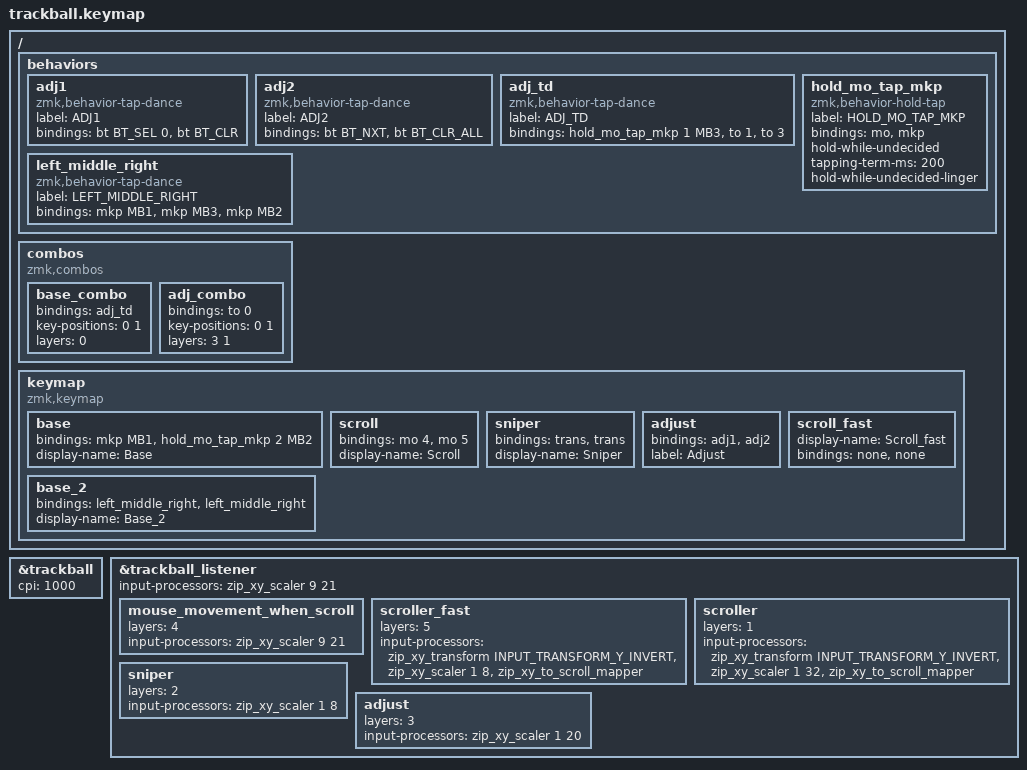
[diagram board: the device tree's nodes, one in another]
#include "keys_ru.h"
#include <dt-bindings/zmk/input_transform.h>
#include <input/processors.dtsi>
#include <zephyr/dt-bindings/input/input-event-codes.h>
#include <behaviors.dtsi>
#include <dt-bindings/zmk/bt.h>
#include <dt-bindings/zmk/pointing.h>

/ {
    behaviors {
        adj1: adj1 {
            compatible = "zmk,behavior-tap-dance";
            label = "ADJ1";
            #binding-cells = <0>;
            bindings = <&bt BT_SEL 0>, <&bt BT_CLR>;
        };

        adj2: adj2 {
            compatible = "zmk,behavior-tap-dance";
            label = "ADJ2";
            #binding-cells = <0>;
            bindings = <&bt BT_NXT>, <&bt BT_CLR_ALL>;
        };

        adj_td: adj_td {
            compatible = "zmk,behavior-tap-dance";
            label = "ADJ_TD";
            #binding-cells = <0>;
            bindings = <&hold_mo_tap_mkp 1 MB3>, <&to 1>, <&to 3>;
        };

        hold_mo_tap_mkp: hold_mo_tap_mkp {
            compatible = "zmk,behavior-hold-tap";
            label = "HOLD_MO_TAP_MKP";
            bindings = <&mo>, <&mkp>;

            #binding-cells = <2>;
            hold-while-undecided;
            tapping-term-ms = <200>;
            hold-while-undecided-linger;
        };

        left_middle_right: left_middle_right {
            compatible = "zmk,behavior-tap-dance";
            label = "LEFT_MIDDLE_RIGHT";
            #binding-cells = <0>;
            bindings = <&mkp MB1>, <&mkp MB3>, <&mkp MB2>;
        };
    };

    combos {
        compatible = "zmk,combos";

        base_combo {
            bindings = <&adj_td>;
            key-positions = <0 1>;
            layers = <0>;
        };

        adj_combo {
            bindings = <&to 0>;
            key-positions = <0 1>;
            layers = <3 1>;
        };
    };

    keymap {
        compatible = "zmk,keymap";

        base {
            bindings = <
&mkp MB1  &hold_mo_tap_mkp 2 MB2
            >;

            display-name = "Base";
        };

        scroll {
            bindings = <
&mo 4  &mo 5
            >;

            display-name = "Scroll";
        };

        sniper {
            bindings = <
&trans  &trans
            >;

            display-name = "Sniper";
        };

        adjust {
            bindings = <
&adj1  &adj2
            >;

            label = "Adjust";
        };

        base_2 {
            bindings = <
&left_middle_right  &left_middle_right
            >;

            display-name = "Base_2";
        };

        scroll_fast {
            display-name = "Scroll_fast";
            bindings = <
&none  &none
            >;
        };
    };
};

&trackball { cpi = <1000>; };

&trackball_listener {
    input-processors = <&zip_xy_scaler 9 21>;

    mouse_movement_when_scroll {
        layers = <4>;
        input-processors = <&zip_xy_scaler 9 21>;
    };

    scroller_fast {
        layers = <5>;
        input-processors =
            <&zip_xy_transform INPUT_TRANSFORM_Y_INVERT>,
            <&zip_xy_scaler 1 8>,
            <&zip_xy_to_scroll_mapper>;
    };

    scroller {
        layers = <1>;
        input-processors =
            <&zip_xy_transform INPUT_TRANSFORM_Y_INVERT>,
            <&zip_xy_scaler 1 32>,
            <&zip_xy_to_scroll_mapper>;
    };

    sniper {
        layers = <2>;
        input-processors = <&zip_xy_scaler 1 8>;
    };

    adjust {
        layers = <3>;
        input-processors = <&zip_xy_scaler 1 20>;
    };
};
